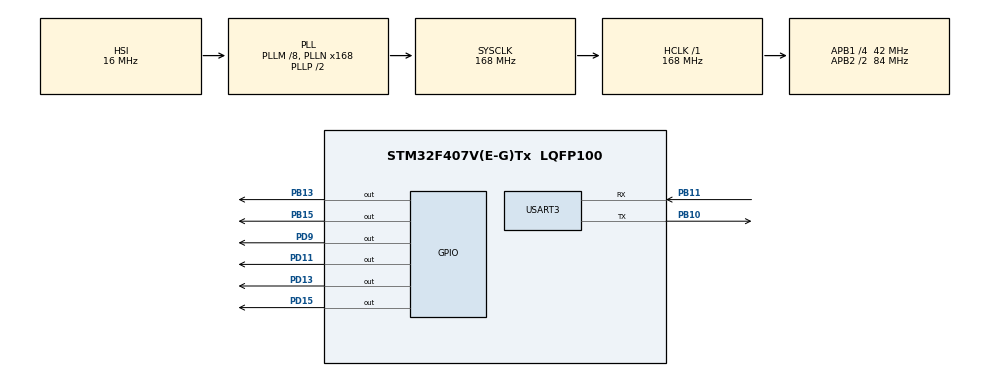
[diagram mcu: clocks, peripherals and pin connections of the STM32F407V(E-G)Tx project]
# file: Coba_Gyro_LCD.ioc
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Dma.Request0=USART3_RX
Dma.USART3_RX.0.Direction=DMA_PERIPH_TO_MEMORY
Dma.USART3_RX.0.FIFOMode=DMA_FIFOMODE_DISABLE
Dma.USART3_RX.0.Instance=DMA1_Stream1
Dma.USART3_RX.0.MemDataAlignment=DMA_MDATAALIGN_BYTE
Dma.USART3_RX.0.MemInc=DMA_MINC_ENABLE
Dma.USART3_RX.0.Mode=DMA_CIRCULAR
Dma.USART3_RX.0.PeriphDataAlignment=DMA_PDATAALIGN_BYTE
Dma.USART3_RX.0.PeriphInc=DMA_PINC_DISABLE
Dma.USART3_RX.0.Priority=DMA_PRIORITY_LOW
Mcu.Family=STM32F4
Mcu.Name=STM32F407V(E-G)Tx
Mcu.Package=LQFP100
NVIC.DMA1_Stream1_IRQn=true\:0\:0\:false\:false\:true\:false
NVIC.PriorityGroup=NVIC_PRIORITYGROUP_4
PB10.Mode=Asynchronous
PB10.Signal=USART3_TX
PB11.Mode=Asynchronous
PB11.Signal=USART3_RX
PB13.Signal=GPIO_Output
PB15.Signal=GPIO_Output
PD11.Signal=GPIO_Output
PD13.Signal=GPIO_Output
PD15.Signal=GPIO_Output
PD9.Signal=GPIO_Output
PH0-OSC_IN.Mode=HSE-External-Oscillator
PH0-OSC_IN.Signal=RCC_OSC_IN
PH1-OSC_OUT.Mode=HSE-External-Oscillator
PH1-OSC_OUT.Signal=RCC_OSC_OUT
ProjectManager.HeapSize=0x200
ProjectManager.StackSize=0x400
ProjectManager.TargetToolchain=TrueSTUDIO
RCC.48MHZClocksFreq_Value=84000000
RCC.AHBFreq_Value=168000000
RCC.APB1CLKDivider=RCC_HCLK_DIV4
RCC.APB1Freq_Value=42000000
RCC.APB1TimFreq_Value=84000000
RCC.APB2CLKDivider=RCC_HCLK_DIV2
RCC.APB2Freq_Value=84000000
RCC.APB2TimFreq_Value=168000000
RCC.CortexFreq_Value=168000000
RCC.HCLKFreq_Value=168000000
RCC.HSE_VALUE=25000000
RCC.HSI_VALUE=16000000
RCC.LSE_VALUE=32768
RCC.PLLM=8
RCC.PLLN=168
RCC.SYSCLKFreq_VALUE=168000000
RCC.SYSCLKSource=RCC_SYSCLKSOURCE_PLLCLK
RCC.VCOOutputFreq_Value=336000000
USART3.VirtualMode=VM_ASYNC
board=Coba_Gyro_LCD

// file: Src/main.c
/**
  ******************************************************************************
  * File Name          : main.c
  * Description        : Main program body
  ******************************************************************************
  ** This notice applies to any and all portions of this file
  * that are not between comment pairs USER CODE BEGIN and
  * USER CODE END. Other portions of this file, whether
  * inserted by the user or by software development tools
  * are owned by their respective copyright owners.
  *
  * COPYRIGHT(c) 2018 STMicroelectronics
  *
  * Redistribution and use in source and binary forms, with or without modification,
  * are permitted provided that the following conditions are met:
  *   1. Redistributions of source code must retain the above copyright notice,
  *      this list of conditions and the following disclaimer.
  *   2. Redistributions in binary form must reproduce the above copyright notice,
  *      this list of conditions and the following disclaimer in the documentation
  *      and/or other materials provided with the distribution.
  *   3. Neither the name of STMicroelectronics nor the names of its contributors
  *      may be used to endorse or promote products derived from this software
  *      without specific prior written permission.
  *
  * THIS SOFTWARE IS PROVIDED BY THE COPYRIGHT HOLDERS AND CONTRIBUTORS "AS IS"
  * AND ANY EXPRESS OR IMPLIED WARRANTIES, INCLUDING, BUT NOT LIMITED TO, THE
  * IMPLIED WARRANTIES OF MERCHANTABILITY AND FITNESS FOR A PARTICULAR PURPOSE ARE
  * DISCLAIMED. IN NO EVENT SHALL THE COPYRIGHT HOLDER OR CONTRIBUTORS BE LIABLE
  * FOR ANY DIRECT, INDIRECT, INCIDENTAL, SPECIAL, EXEMPLARY, OR CONSEQUENTIAL
  * DAMAGES (INCLUDING, BUT NOT LIMITED TO, PROCUREMENT OF SUBSTITUTE GOODS OR
  * SERVICES; LOSS OF USE, DATA, OR PROFITS; OR BUSINESS INTERRUPTION) HOWEVER
  * CAUSED AND ON ANY THEORY OF LIABILITY, WHETHER IN CONTRACT, STRICT LIABILITY,
  * OR TORT (INCLUDING NEGLIGENCE OR OTHERWISE) ARISING IN ANY WAY OUT OF THE USE
  * OF THIS SOFTWARE, EVEN IF ADVISED OF THE POSSIBILITY OF SUCH DAMAGE.
  *
  ******************************************************************************
  */

#include "main.h"
#include "stm32f4xx_hal.h"
#include "STM_MY_LCD16X2.h"
#include "stdio.h"
#include "stdlib.h"
#include "math.h"
#include "string.h"

UART_HandleTypeDef huart3;
DMA_HandleTypeDef hdma_usart3_rx;

/* USER CODE BEGIN PV */
/* Private variables ---------------------------------------------------------*/

/* USER CODE END PV */

void SystemClock_Config(void);
static void MX_GPIO_Init(void);
static void MX_DMA_Init(void);
static void MX_USART3_UART_Init(void);

/* USER CODE BEGIN PFP */
/* Private function prototypes -----------------------------------------------*/

/* USER CODE END PFP */

/* USER CODE BEGIN 0 */
char data_terima[7] = {'i','t','s'};
float gyro_buffer = 0, gyro_offset = 90;
float gyro_derajat = 90, gyro_radian = 1.5707963268;

/* USER CODE END 0 */

int main(void)
{

  /* MCU Configuration----------------------------------------------------------*/

  /* Reset of all peripherals, Initializes the Flash interface and the Systick. */
  HAL_Init();

  /* Configure the system clock */
  SystemClock_Config();

  /* Initialize all configured peripherals */
  MX_GPIO_Init();
  MX_DMA_Init();
  MX_USART3_UART_Init();

  LCD1602_Begin4BIT(GPIOB, GPIO_PIN_13, GPIO_PIN_15, GPIOD, GPIO_PIN_9, GPIO_PIN_11, GPIO_PIN_13, GPIO_PIN_15);
  LCD1602_noCursor();
  LCD1602_noBlink();

  HAL_UART_Receive_DMA(&huart3, (uint8_t*)data_terima, 7);

  /* Infinite loop */
  while (1)
  {

	  memcpy(&gyro_buffer, data_terima + 3, 4);

	  gyro_derajat = (gyro_offset - gyro_buffer);
	  gyro_radian = (gyro_offset - gyro_buffer) * 0.01745329252;

	  while(gyro_derajat > 180) gyro_derajat -= 360;
	  while(gyro_derajat < -180) gyro_derajat +=360;

	  while(gyro_radian > 3.14159265359) gyro_radian -= 6.28318530718;
	  while(gyro_radian < -3.14159265359) gyro_radian += 6.28318530718;

	  LCD1602_clear();

	  LCD1602_setCursor(1,1);
	  LCD1602_PrintInt(gyro_derajat);

	  HAL_Delay(200);

  }

}

/** System Clock Configuration
*/
void SystemClock_Config(void)
{

  RCC_OscInitTypeDef RCC_OscInitStruct;
  RCC_ClkInitTypeDef RCC_ClkInitStruct;

    /**Configure the main internal regulator output voltage
    */
  __HAL_RCC_PWR_CLK_ENABLE();

  __HAL_PWR_VOLTAGESCALING_CONFIG(PWR_REGULATOR_VOLTAGE_SCALE1);

    /**Initializes the CPU, AHB and APB busses clocks
    */
  RCC_OscInitStruct.OscillatorType = RCC_OSCILLATORTYPE_HSI;
  RCC_OscInitStruct.HSIState = RCC_HSI_ON;
  RCC_OscInitStruct.HSICalibrationValue = 16;
  RCC_OscInitStruct.PLL.PLLState = RCC_PLL_ON;
  RCC_OscInitStruct.PLL.PLLSource = RCC_PLLSOURCE_HSI;
  RCC_OscInitStruct.PLL.PLLM = 8;
  RCC_OscInitStruct.PLL.PLLN = 168;
  RCC_OscInitStruct.PLL.PLLP = RCC_PLLP_DIV2;
  RCC_OscInitStruct.PLL.PLLQ = 4;
  if (HAL_RCC_OscConfig(&RCC_OscInitStruct) != HAL_OK)
  {
    _Error_Handler(__FILE__, __LINE__);
  }

    /**Initializes the CPU, AHB and APB busses clocks
    */
  RCC_ClkInitStruct.ClockType = RCC_CLOCKTYPE_HCLK|RCC_CLOCKTYPE_SYSCLK
                              |RCC_CLOCKTYPE_PCLK1|RCC_CLOCKTYPE_PCLK2;
  RCC_ClkInitStruct.SYSCLKSource = RCC_SYSCLKSOURCE_PLLCLK;
  RCC_ClkInitStruct.AHBCLKDivider = RCC_SYSCLK_DIV1;
  RCC_ClkInitStruct.APB1CLKDivider = RCC_HCLK_DIV4;
  RCC_ClkInitStruct.APB2CLKDivider = RCC_HCLK_DIV2;

  if (HAL_RCC_ClockConfig(&RCC_ClkInitStruct, FLASH_LATENCY_5) != HAL_OK)
  {
    _Error_Handler(__FILE__, __LINE__);
  }

    /**Configure the Systick interrupt time
    */
  HAL_SYSTICK_Config(HAL_RCC_GetHCLKFreq()/1000);

    /**Configure the Systick
    */
  HAL_SYSTICK_CLKSourceConfig(SYSTICK_CLKSOURCE_HCLK);

  /* SysTick_IRQn interrupt configuration */
  HAL_NVIC_SetPriority(SysTick_IRQn, 0, 0);
}

/* USART3 init function */
static void MX_USART3_UART_Init(void)
{

  huart3.Instance = USART3;
  huart3.Init.BaudRate = 115200;
  huart3.Init.WordLength = UART_WORDLENGTH_8B;
  huart3.Init.StopBits = UART_STOPBITS_1;
  huart3.Init.Parity = UART_PARITY_NONE;
  huart3.Init.Mode = UART_MODE_TX_RX;
  huart3.Init.HwFlowCtl = UART_HWCONTROL_NONE;
  huart3.Init.OverSampling = UART_OVERSAMPLING_16;
  if (HAL_UART_Init(&huart3) != HAL_OK)
  {
    _Error_Handler(__FILE__, __LINE__);
  }

}

static void MX_DMA_Init(void)
{
  /* DMA controller clock enable */
  __HAL_RCC_DMA1_CLK_ENABLE();

  /* DMA interrupt init */
  /* DMA1_Stream1_IRQn interrupt configuration */
  HAL_NVIC_SetPriority(DMA1_Stream1_IRQn, 0, 0);
  HAL_NVIC_EnableIRQ(DMA1_Stream1_IRQn);

}

/** Configure pins as
        * Analog
        * Input
        * Output
        * EVENT_OUT
        * EXTI
*/
static void MX_GPIO_Init(void)
{

  GPIO_InitTypeDef GPIO_InitStruct;

  /* GPIO Ports Clock Enable */
  __HAL_RCC_GPIOH_CLK_ENABLE();
  __HAL_RCC_GPIOB_CLK_ENABLE();
  __HAL_RCC_GPIOD_CLK_ENABLE();

  /*Configure GPIO pin Output Level */
  HAL_GPIO_WritePin(GPIOB, GPIO_PIN_13|GPIO_PIN_15, GPIO_PIN_RESET);

  /*Configure GPIO pin Output Level */
  HAL_GPIO_WritePin(GPIOD, GPIO_PIN_9|GPIO_PIN_11|GPIO_PIN_13|GPIO_PIN_15, GPIO_PIN_RESET);

  /*Configure GPIO pins : PB13 PB15 */
  GPIO_InitStruct.Pin = GPIO_PIN_13|GPIO_PIN_15;
  GPIO_InitStruct.Mode = GPIO_MODE_OUTPUT_PP;
  GPIO_InitStruct.Pull = GPIO_NOPULL;
  GPIO_InitStruct.Speed = GPIO_SPEED_FREQ_LOW;
  HAL_GPIO_Init(GPIOB, &GPIO_InitStruct);

  /*Configure GPIO pins : PD9 PD11 PD13 PD15 */
  GPIO_InitStruct.Pin = GPIO_PIN_9|GPIO_PIN_11|GPIO_PIN_13|GPIO_PIN_15;
  GPIO_InitStruct.Mode = GPIO_MODE_OUTPUT_PP;
  GPIO_InitStruct.Pull = GPIO_NOPULL;
  GPIO_InitStruct.Speed = GPIO_SPEED_FREQ_LOW;
  HAL_GPIO_Init(GPIOD, &GPIO_InitStruct);

}

void _Error_Handler(char * file, int line)
{
  while(1)
  {
  }
}

/************************ (C) COPYRIGHT STMicroelectronics *****END OF FILE****/
